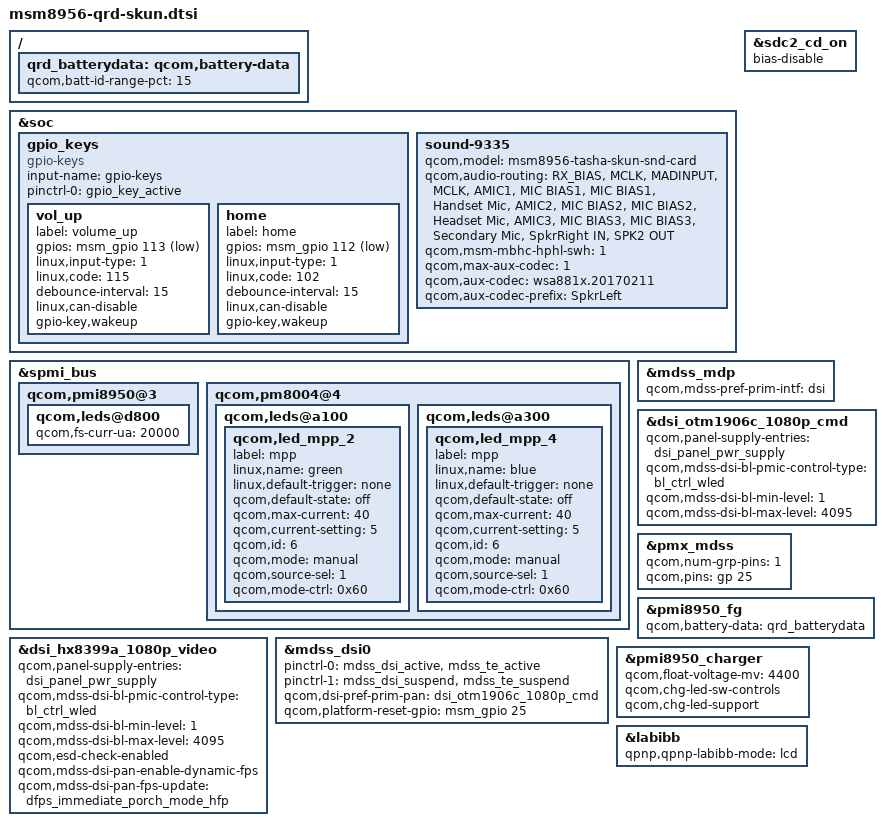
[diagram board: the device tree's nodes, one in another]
// SPDX-License-Identifier: GPL-2.0
// Copyright (c) 2015, The Linux Foundation. All rights reserved.
// Copyright (c) 2022, Benarji Anand <benarji385@gmail.com>

#include "msm8956-qrd.dtsi"
#include "msm8956-camera-sensor-qrd.dtsi"
#include "msm8956-mdss-panels.dtsi"

&soc {
	gpio_keys {
		compatible = "gpio-keys";
		input-name = "gpio-keys";
		pinctrl-names = "default";
		pinctrl-0 = <&gpio_key_active>;

		vol_up {
			label = "volume_up";
			gpios = <&msm_gpio 113 0x1>;
			linux,input-type = <1>;
			linux,code = <115>;
			debounce-interval = <15>;
			linux,can-disable;
                        gpio-key,wakeup;
		};

		home {
			label = "home";
			gpios = <&msm_gpio 112 0x1>;
			linux,input-type = <1>;
			linux,code = <102>;
			debounce-interval = <15>;
			linux,can-disable;
                        gpio-key,wakeup;
		};
	};

	sound-9335 {
		qcom,model = "msm8956-tasha-skun-snd-card";

		qcom,audio-routing =
			"RX_BIAS", "MCLK",
			"MADINPUT", "MCLK",
			"AMIC1", "MIC BIAS1",
			"MIC BIAS1", "Handset Mic",
			"AMIC2", "MIC BIAS2",
			"MIC BIAS2", "Headset Mic",
			"AMIC3", "MIC BIAS3",
			"MIC BIAS3", "Secondary Mic",
			"SpkrRight IN", "SPK2 OUT";

		qcom,msm-mbhc-hphl-swh = <1>;
		qcom,max-aux-codec = <1>;
		qcom,aux-codec = "wsa881x.20170211";
		qcom,aux-codec-prefix = "SpkrLeft";
	};
};

&spmi_bus {
        qcom,pmi8950@3 {
                qcom,leds@d800 {
                        qcom,fs-curr-ua = <20000>;
                };
        };

	qcom,pm8004@4 {
		qcom,leds@a100 {
			status = "okay";
			qcom,led_mpp_2 {
				label = "mpp";
				linux,name = "green";
				linux,default-trigger = "none";
				qcom,default-state = "off";
				qcom,max-current = <40>;
				qcom,current-setting = <5>;
				qcom,id = <6>;
				qcom,mode = "manual";
				qcom,source-sel = <1>;
				qcom,mode-ctrl = <0x60>;
			};
		};

		qcom,leds@a300 {
			status = "okay";
			qcom,led_mpp_4 {
				label = "mpp";
				linux,name = "blue";
				linux,default-trigger = "none";
				qcom,default-state = "off";
				qcom,max-current = <40>;
				qcom,current-setting = <5>;
				qcom,id = <6>;
				qcom,mode = "manual";
				qcom,source-sel = <1>;
				qcom,mode-ctrl = <0x60>;
			};
		};
	};
};

&sdc2_cd_on {
	/delete-property/ bias-pull-up;
	bias-disable;
};

&mdss_mdp {
	qcom,mdss-pref-prim-intf = "dsi";
};

&dsi_otm1906c_1080p_cmd {
	qcom,panel-supply-entries = <&dsi_panel_pwr_supply>;
	qcom,mdss-dsi-bl-pmic-control-type = "bl_ctrl_wled";
	qcom,mdss-dsi-bl-min-level = <1>;
	qcom,mdss-dsi-bl-max-level = <4095>;
};

&dsi_hx8399a_1080p_video {
	qcom,panel-supply-entries = <&dsi_panel_pwr_supply>;
	qcom,mdss-dsi-bl-pmic-control-type = "bl_ctrl_wled";
	qcom,mdss-dsi-bl-min-level = <1>;
	qcom,mdss-dsi-bl-max-level = <4095>;
	qcom,esd-check-enabled;
	qcom,mdss-dsi-pan-enable-dynamic-fps;
	qcom,mdss-dsi-pan-fps-update = "dfps_immediate_porch_mode_hfp";
};

&pmx_mdss {
	qcom,num-grp-pins = <1>;
	qcom,pins = <&gp 25>;
};

&mdss_dsi0 {
	pinctrl-names = "mdss_default", "mdss_sleep";
	pinctrl-0 = <&mdss_dsi_active &mdss_te_active>;
	pinctrl-1 = <&mdss_dsi_suspend &mdss_te_suspend>;
	qcom,dsi-pref-prim-pan = <&dsi_otm1906c_1080p_cmd>;

	qcom,platform-reset-gpio = <&msm_gpio 25 0>;
};

/ {
	qrd_batterydata: qcom,battery-data {
		qcom,batt-id-range-pct = <15>;
		#include "batterydata-qrd-skum-4v4-2920mah.dtsi"
	};
};

&pmi8950_fg {
	qcom,battery-data = <&qrd_batterydata>;
};

&pmi8950_charger {
	qcom,float-voltage-mv = <4400>;
	qcom,chg-led-sw-controls;
	qcom,chg-led-support;
	status = "okay";
};

&labibb {
	status = "ok";
	qpnp,qpnp-labibb-mode = "lcd";
};
